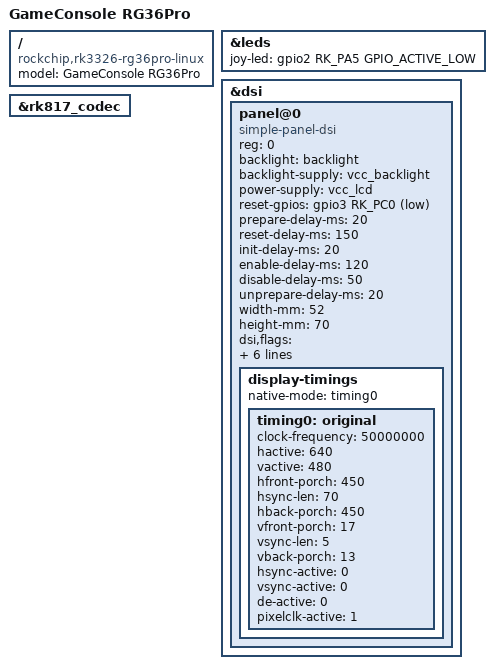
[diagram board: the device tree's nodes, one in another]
// SPDX-License-Identifier: (GPL-2.0+ OR MIT)
/*
* Copyright (c) 2026 kk&lcdyk
*
* GameConsole RG36Pro
*
*/

/dts-v1/;
#include "rk3326-r36s-panel4-type1-linux.dts"

/ {
	model = "GameConsole RG36Pro";
	compatible = "rockchip,rk3326-rg36pro-linux", "rockchip,rk3326";
};

&leds {
	joy-led = <&gpio2 RK_PA5 GPIO_ACTIVE_LOW>;
};

&dsi {
	status = "okay";
	
	panel@0 {
		compatible = "simple-panel-dsi";
		reg = <0>;
		/* pwm1 backlight */
		backlight = <&backlight>;
		/* RK817 LDO7 */
		backlight-supply = <&vcc_backlight>;
		/* RK817 LDO8 */
		power-supply = <&vcc_lcd>;
		/* Rev 0.2 LCD reset gpio GPIO3.C0 */
		reset-gpios = <&gpio3 RK_PC0 GPIO_ACTIVE_LOW>;
		prepare-delay-ms = <20>;
		reset-delay-ms = <150>;
		init-delay-ms = <20>;
		enable-delay-ms = <120>;
		disable-delay-ms = <50>;
		unprepare-delay-ms = <20>;
		width-mm = <52>;
		height-mm = <70>;
		dsi,flags  = <(MIPI_DSI_MODE_VIDEO |
		MIPI_DSI_MODE_VIDEO_BURST |
		MIPI_DSI_MODE_LPM |
		MIPI_DSI_MODE_EOT_PACKET)>;
		dsi,format = <MIPI_DSI_FMT_RGB888>;
		dsi,lanes = <4>;
		panel-init-sequence = [39 00 04 b9 f1 12 83 39 00 06 b1 00 00 00 da 80 39 00 04 b2 00 13 70 39 00 0b b3 10 10 28 28 03 ff 00 00 00 00 15 00 02 b4 80 15 00 03 b5 0a 0a 15 00 03 b6 82 82 39 00 05 b8 26 62 f0 63 39 00 1c ba 33 81 05 f9 0e 0e 20 00 00 00 00 00 00 00 44 25 00 90 0a 00 00 01 4f 01 00 00 37 15 00 02 bc 47 39 00 04 bf 02 11 00 39 00 0a c0 73 73 50 50 00 00 12 50 00 39 00 0d c1 53 00 32 32 77 d1 cc cc 77 77 33 33 39 00 07 c6 82 00 bf ff 00 ff 39 00 07 c7 b8 00 0a 00 00 00 39 00 05 c8 10 40 1e 02 15 00 02 cc 0b 39 00 23 e0 00 07 0d 37 35 3f 41 44 06 0c 0d 0f 11 10 12 14 1a 00 07 0d 37 35 3f 41 44 06 0c 0d 0f 11 10 12 14 1a 39 00 0f e3 07 07 0b 0b 0b 0b 00 00 00 00 ff 00 c0 10 39 00 40 e9 c8 10 02 00 00 b0 b1 11 31 23 28 80 b0 b1 27 08 00 04 02 00 00 00 00 04 02 00 00 00 88 88 ba 60 24 08 88 88 88 88 88 88 88 ba 71 35 18 88 88 88 88 88 00 00 00 01 00 00 00 00 00 00 00 00 00 39 00 3e ea 97 0a 82 02 03 07 00 00 00 00 00 00 81 88 ba 17 53 88 88 88 88 88 88 80 88 ba 06 42 88 88 88 88 88 88 23 00 00 02 80 00 00 00 00 00 00 00 00 00 00 00 00 00 00 00 00 00 00 00 00 00 00 39 00 04 ef ff ff 01 05 c8 01 11 05 14 01 29];
		panel-exit-sequence = <0x5140128 0x50a0110>;
		
		display-timings {
			native-mode = <&timing0>;
			
			// 50.00MHz / (640+450+70+450)×(480+17+5+13) = 1610×515 = 60.30 Hz
			timing0: original {
				clock-frequency = <50000000>;
				hactive = <640>;
				vactive = <480>;
				hfront-porch = <450>;
				hsync-len = <70>;
				hback-porch = <450>;
				vfront-porch = <17>;
				vsync-len = <5>;
				vback-porch = <13>;
				hsync-active = <0>;
				vsync-active = <0>;
				de-active = <0>;
				pixelclk-active = <1>;
			};
		};
	};
};

&rk817_codec {
    /delete-property/ spk-mute-delay-ms;
    /delete-property/ use-ext-amplifier;
};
